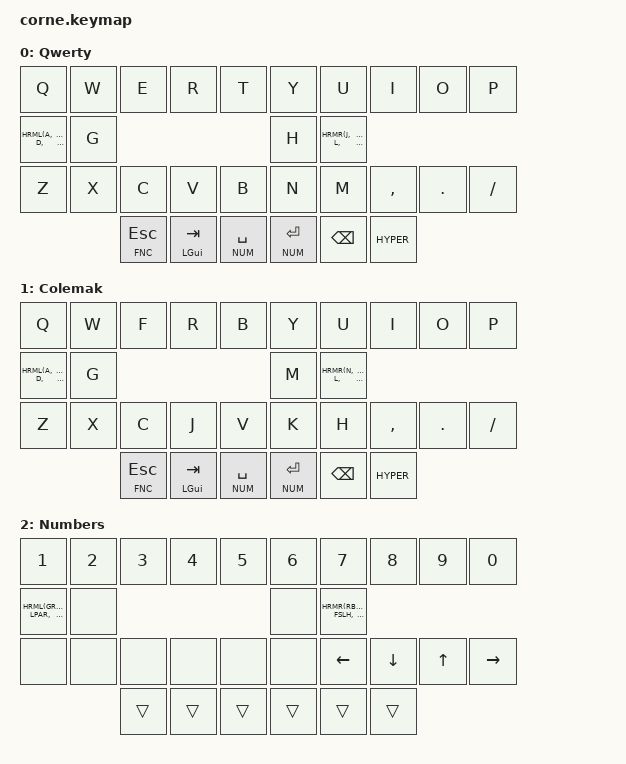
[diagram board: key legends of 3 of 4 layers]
/*
 * Copyright (c) 2020 The ZMK Contributors
 *
 * SPDX-License-Identifier: MIT
 */

#include <behaviors.dtsi>
#include <dt-bindings/zmk/keys.h>
#include <dt-bindings/zmk/bt.h>
#include "includes/layers.dtsi"
#include "includes/homerow.dtsi"

#define HYPER  RS(RC(RA(RGUI)))

/ {
  chosen {
    zmk,physical-layout = &foostan_corne_5col_layout;
  };

  behaviors {
    htl: hold_tap_left {
      #binding-cells = <2>;
      bindings = <&kp>, <&kp>;
      label = "hold_tap_left";
      compatible = "zmk,behavior-hold-tap";

      flavor = "balanced";
      tapping-term-ms = <200>;
      quick-tap-ms = <175>;
      require-prior-idle-ms = <130>;
      hold-trigger-key-positions = <KEYS_R>;
      // hold-trigger-key-positions = <KEYS_R THUMBS>;
      hold-trigger-on-release;
    };

    htr: hold_tap_right {
      #binding-cells = <2>;
      bindings = <&kp>, <&kp>;
      label = "hold_tap_right";
      compatible = "zmk,behavior-hold-tap";

      flavor = "balanced";
      tapping-term-ms = <200>;
      quick-tap-ms = <175>;
      require-prior-idle-ms = <130>;
      hold-trigger-key-positions = <KEYS_L>;
      // hold-trigger-key-positions = <KEYS_L THUMBS>;
      hold-trigger-on-release;
    };

    bspc_del: backspace_delete {
      #binding-cells = <0>;
      mods = <(MOD_LCTL|MOD_RCTL)>;
      compatible = "zmk,behavior-mod-morph";
      bindings = <&kp BACKSPACE>, <&kp DELETE>;
    };

    bt_safe_clr: bluetooth_safe_clear {
      label = "bluetooth_safe_clear";
      compatible = "zmk,behavior-tap-dance";
      #binding-cells = <0>;
      bindings = <&none>, <&none>, <&bt BT_CLR>;
    };
  };

  combos {
    compatible = "zmk,combos";

    combo_to_qwerty {
      layers = <COL>;
      timeout-ms = <40>;
      bindings = <&to QWE>;
      key-positions = <LTHM1 RTHM1>;
    };

    combo_to_colemak {
      layers = <QWE>;
      timeout-ms = <40>;
      bindings = <&to COL>;
      key-positions = <LTHM1 RTHM1>;
    };

    combo_minus {
      timeout-ms = <40>;
      bindings = <&kp MINUS>;
      key-positions = <LTOP4 RTOP4>;
    };

    combo_equal {
      timeout-ms = <40>;
      bindings = <&kp EQUAL>;
      key-positions = <LMID4 RMID4>;
    };

    combo_plus {
      timeout-ms = <40>;
      bindings = <&kp PLUS>;
      key-positions = <LMID3 RMID3>;
    };

    combo_lodash {
      timeout-ms = <40>;
      bindings = <&kp UNDERSCORE>;
      key-positions = <LBOT4 RBOT4>;
    };
  };

  keymap {
    compatible = "zmk,keymap";

    qwerty {
      display-name = "Qwerty";
      bindings = <
// ╭─────────────┬─────────────┬─────────────┬───────────────┬────────────────╮   ╭───────────────┬───────────────┬─────────────┬─────────────┬───────────────╮
     &kp Q        &kp W        &kp E        &kp R          &kp T                &kp Y          &kp U          &kp I        &kp O        &kp P
// ├─────────────┼─────────────┼─────────────┼───────────────┼────────────────┤   ├───────────────┼───────────────┼─────────────┼─────────────┼───────────────┤
    HRML(A,           S,           D,           F)         &kp G                &kp H         HRMR(J,          K,           L,          SEMI)
// ├─────────────┼─────────────┼─────────────┼───────────────┼────────────────┤   ├───────────────┼───────────────┼─────────────┼─────────────┼───────────────┤
     &kp Z        &kp X        &kp C        &kp V          &kp B                &kp N          &kp M          &kp COMMA    &kp DOT      &kp FSLH
// ╰─────────────┴─────────────┴─────────────┼───────────────┼────────────────┤   ├───────────────┼───────────────┼─────────────┼─────────────┴───────────────╯
                               &lt FNC ESC  &htl LGUI TAB  &lt NUM SPACE        &lt NUM RET   &kp BACKSPACE   &kp HYPER
//                           ╰─────────────┴───────────────┴─────────────────╯   ╰──────────────┴───────────────┴─────────────╯
      >;
    };

    colemak {
      display-name = "Colemak";
      bindings = <
// Note, this is currently Tarmak v1a
// ╭─────────────┬─────────────┬─────────────┬───────────────┬────────────────╮   ╭───────────────┬───────────────┬─────────────┬─────────────┬───────────────╮
     &kp Q        &kp W        &kp F        &kp R          &kp B                &kp Y          &kp U          &kp I        &kp O        &kp P
// ├─────────────┼─────────────┼─────────────┼───────────────┼────────────────┤   ├───────────────┼───────────────┼─────────────┼─────────────┼───────────────┤
    HRML(A,           S,           D,           T)         &kp G                &kp M         HRMR(N,           E,           L,          SEMI)
// ├─────────────┼─────────────┼─────────────┼───────────────┼────────────────┤   ├───────────────┼───────────────┼─────────────┼─────────────┼───────────────┤
     &kp Z        &kp X        &kp C        &kp J          &kp V                &kp K          &kp H          &kp COMMA    &kp DOT      &kp FSLH
// ╰─────────────┴─────────────┴─────────────┼───────────────┼────────────────┤   ├───────────────┼───────────────┼─────────────┼─────────────┴───────────────╯
                               &lt FNC ESC  &htl LGUI TAB  &lt NUM SPACE        &lt NUM RET   &kp BACKSPACE   &kp HYPER
//                           ╰─────────────┴───────────────┴─────────────────╯   ╰──────────────┴───────────────┴─────────────╯
      >;
    };

    numbers {
      display-name = "Numbers";
      bindings = <
// ╭─────────────┬─────────────┬─────────────┬─────────────┬─────────────╮   ╭─────────────┬─────────────┬─────────────┬─────────────┬─────────────╮
    &kp N1       &kp N2       &kp N3       &kp N4       &kp N5           &kp N6       &kp N7        &kp N8       &kp N9        &kp N0
// ├─────────────┼─────────────┼─────────────┼─────────────┼─────────────┤   ├─────────────┼─────────────┼─────────────┼─────────────┼─────────────┤
    HRML(GRAVE,   BSLH,         LPAR,         LBKT)     &none             &none        HRMR(RBKT,      RPAR,         FSLH,       SQT)
// ├─────────────┼─────────────┼─────────────┼─────────────┼─────────────┤   ├─────────────┼─────────────┼─────────────┼─────────────┼─────────────┤
    &none        &none        &none        &none        &none            &none        &kp LEFT     &kp DOWN     &kp UP       &kp RIGHT
// ╰─────────────┴─────────────┼─────────────┼─────────────┼─────────────┤   ├─────────────┼─────────────┼─────────────┼─────────────┴─────────────╯
                               &trans       &trans       &trans           &trans       &trans       &trans
//                           ╰─────────────┴─────────────┴─────────────╯   ╰─────────────┴─────────────┴─────────────╯
      >;
    };

    functions {
      display-name = "F(x)";
      bindings = <
// ╭─────────────┬──────────────┬──────────────────────────────────────┬──────────────┬─────────────╮   ╭─────────────┬─────────────┬─────────────┬──────────────┬─────────────╮
    &kp C_BRI_DN  &kp C_BRI_UP  &kp C_AC_DESKTOP_SHOW_ALL_WINDOWS   &bt_safe_clr   &kp C_PREV       &kp C_NEXT   &kp C_PP     &kp C_MUTE   &kp C_VOL_DN  &kp C_VOL_UP
// ├─────────────┼──────────────┼──────────────────────────────────────┼──────────────┼─────────────┤   ├─────────────┼─────────────┼─────────────┼──────────────┼─────────────┤
    &kp LSHFT     &kp LCTL      &kp LALT                            &kp LGUI       &none            &none        &kp RGUI     &kp RALT     &kp RCTL      &kp RSHFT
// ├─────────────┼──────────────┼──────────────────────────────────────┼──────────────┼─────────────┤   ├─────────────┼─────────────┼─────────────┼──────────────┼─────────────┤
    &none         &none         &none                               &none          &none            &none        &none        &none        &none         &none
// ╰─────────────┴──────────────┴───────────────────────┬──────────────┼──────────────┼─────────────┤   ├─────────────┼─────────────┼─────────────┼──────────────┴─────────────╯
                                                      &trans        &trans         &trans           &trans       &trans       &trans
//                                                   ╰──────────────┴──────────────┴─────────────╯   ╰─────────────┴─────────────┴─────────────╯
      >;
    };
  };
};
